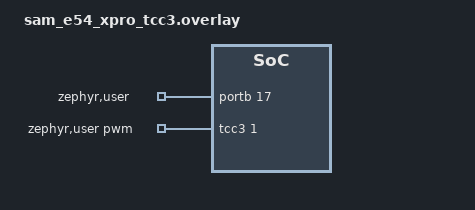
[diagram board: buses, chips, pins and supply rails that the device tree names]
/*
 * SPDX-FileCopyrightText: Copyright 2026 Microchip Technology Inc.
 * SPDX-License-Identifier: Apache-2.0
 */

/* connect PB16 to PB17 */

#define PWM_NODE    tcc3
#define PWM_PINCTRL tcc3_pwm_default
#define PWM_COMPAT "microchip,tcc-g1-pwm"
#include "mchp_pwm_loopback_support.dtsi"

/ {
	zephyr,user {
		pwms = <&tcc3 1 PWM_MSEC(20) 0>;
		gpios = <&portb 17 GPIO_ACTIVE_HIGH>;
	};
};

&portb {
	status = "okay";
};

&pinctrl {
	tcc3_pwm_default: tcc3_pwm_default {
		group1 {
			pinmux = <PB16F_TCC3_WO0>;
		};
	};
};
